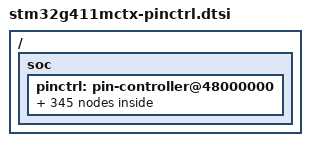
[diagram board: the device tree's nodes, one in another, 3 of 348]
/*
 * NOTE: Autogenerated file using genpinctrl.py
 *
 * SPDX-License-Identifier: Apache-2.0
 */

#include <zephyr/dt-bindings/pinctrl/stm32-pinctrl.h>

/ {
	soc {
		pinctrl: pin-controller@48000000 {

			/* ADC_IN / ADC_INN / ADC_INP */

			/omit-if-no-ref/ adc1_in1_pa0: adc1_in1_pa0 {
				pinmux = <STM32_PINMUX('A', 0, ANALOG)>;
			};

			/omit-if-no-ref/ adc1_in2_pa1: adc1_in2_pa1 {
				pinmux = <STM32_PINMUX('A', 1, ANALOG)>;
			};

			/omit-if-no-ref/ adc1_in3_pa2: adc1_in3_pa2 {
				pinmux = <STM32_PINMUX('A', 2, ANALOG)>;
			};

			/omit-if-no-ref/ adc1_in4_pa3: adc1_in4_pa3 {
				pinmux = <STM32_PINMUX('A', 3, ANALOG)>;
			};

			/omit-if-no-ref/ adc1_in15_pb0: adc1_in15_pb0 {
				pinmux = <STM32_PINMUX('B', 0, ANALOG)>;
			};

			/omit-if-no-ref/ adc1_in12_pb1: adc1_in12_pb1 {
				pinmux = <STM32_PINMUX('B', 1, ANALOG)>;
			};

			/omit-if-no-ref/ adc1_in14_pb11: adc1_in14_pb11 {
				pinmux = <STM32_PINMUX('B', 11, ANALOG)>;
			};

			/omit-if-no-ref/ adc1_in11_pb12: adc1_in11_pb12 {
				pinmux = <STM32_PINMUX('B', 12, ANALOG)>;
			};

			/omit-if-no-ref/ adc1_in5_pb14: adc1_in5_pb14 {
				pinmux = <STM32_PINMUX('B', 14, ANALOG)>;
			};

			/omit-if-no-ref/ adc1_in6_pc0: adc1_in6_pc0 {
				pinmux = <STM32_PINMUX('C', 0, ANALOG)>;
			};

			/omit-if-no-ref/ adc1_in7_pc1: adc1_in7_pc1 {
				pinmux = <STM32_PINMUX('C', 1, ANALOG)>;
			};

			/omit-if-no-ref/ adc1_in8_pc2: adc1_in8_pc2 {
				pinmux = <STM32_PINMUX('C', 2, ANALOG)>;
			};

			/omit-if-no-ref/ adc1_in9_pc3: adc1_in9_pc3 {
				pinmux = <STM32_PINMUX('C', 3, ANALOG)>;
			};

			/omit-if-no-ref/ adc1_in10_pf0: adc1_in10_pf0 {
				pinmux = <STM32_PINMUX('F', 0, ANALOG)>;
			};

			/omit-if-no-ref/ adc2_in1_pa0: adc2_in1_pa0 {
				pinmux = <STM32_PINMUX('A', 0, ANALOG)>;
			};

			/omit-if-no-ref/ adc2_in2_pa1: adc2_in2_pa1 {
				pinmux = <STM32_PINMUX('A', 1, ANALOG)>;
			};

			/omit-if-no-ref/ adc2_in17_pa4: adc2_in17_pa4 {
				pinmux = <STM32_PINMUX('A', 4, ANALOG)>;
			};

			/omit-if-no-ref/ adc2_in13_pa5: adc2_in13_pa5 {
				pinmux = <STM32_PINMUX('A', 5, ANALOG)>;
			};

			/omit-if-no-ref/ adc2_in3_pa6: adc2_in3_pa6 {
				pinmux = <STM32_PINMUX('A', 6, ANALOG)>;
			};

			/omit-if-no-ref/ adc2_in4_pa7: adc2_in4_pa7 {
				pinmux = <STM32_PINMUX('A', 7, ANALOG)>;
			};

			/omit-if-no-ref/ adc2_in12_pb2: adc2_in12_pb2 {
				pinmux = <STM32_PINMUX('B', 2, ANALOG)>;
			};

			/omit-if-no-ref/ adc2_in14_pb11: adc2_in14_pb11 {
				pinmux = <STM32_PINMUX('B', 11, ANALOG)>;
			};

			/omit-if-no-ref/ adc2_in15_pb15: adc2_in15_pb15 {
				pinmux = <STM32_PINMUX('B', 15, ANALOG)>;
			};

			/omit-if-no-ref/ adc2_in6_pc0: adc2_in6_pc0 {
				pinmux = <STM32_PINMUX('C', 0, ANALOG)>;
			};

			/omit-if-no-ref/ adc2_in7_pc1: adc2_in7_pc1 {
				pinmux = <STM32_PINMUX('C', 1, ANALOG)>;
			};

			/omit-if-no-ref/ adc2_in8_pc2: adc2_in8_pc2 {
				pinmux = <STM32_PINMUX('C', 2, ANALOG)>;
			};

			/omit-if-no-ref/ adc2_in9_pc3: adc2_in9_pc3 {
				pinmux = <STM32_PINMUX('C', 3, ANALOG)>;
			};

			/omit-if-no-ref/ adc2_in5_pc4: adc2_in5_pc4 {
				pinmux = <STM32_PINMUX('C', 4, ANALOG)>;
			};

			/omit-if-no-ref/ adc2_in11_pc5: adc2_in11_pc5 {
				pinmux = <STM32_PINMUX('C', 5, ANALOG)>;
			};

			/omit-if-no-ref/ adc2_in10_pf1: adc2_in10_pf1 {
				pinmux = <STM32_PINMUX('F', 1, ANALOG)>;
			};

			/omit-if-no-ref/ adc3_in12_pb0: adc3_in12_pb0 {
				pinmux = <STM32_PINMUX('B', 0, ANALOG)>;
			};

			/omit-if-no-ref/ adc3_in1_pb1: adc3_in1_pb1 {
				pinmux = <STM32_PINMUX('B', 1, ANALOG)>;
			};

			/omit-if-no-ref/ adc3_in5_pb13: adc3_in5_pb13 {
				pinmux = <STM32_PINMUX('B', 13, ANALOG)>;
			};

			/omit-if-no-ref/ adc3_in7_pd10: adc3_in7_pd10 {
				pinmux = <STM32_PINMUX('D', 10, ANALOG)>;
			};

			/omit-if-no-ref/ adc3_in4_pe7: adc3_in4_pe7 {
				pinmux = <STM32_PINMUX('E', 7, ANALOG)>;
			};

			/omit-if-no-ref/ adc3_in6_pe8: adc3_in6_pe8 {
				pinmux = <STM32_PINMUX('E', 8, ANALOG)>;
			};

			/omit-if-no-ref/ adc3_in2_pe9: adc3_in2_pe9 {
				pinmux = <STM32_PINMUX('E', 9, ANALOG)>;
			};

			/omit-if-no-ref/ adc3_in14_pe10: adc3_in14_pe10 {
				pinmux = <STM32_PINMUX('E', 10, ANALOG)>;
			};

			/omit-if-no-ref/ adc3_in15_pe11: adc3_in15_pe11 {
				pinmux = <STM32_PINMUX('E', 11, ANALOG)>;
			};

			/omit-if-no-ref/ adc3_in16_pe12: adc3_in16_pe12 {
				pinmux = <STM32_PINMUX('E', 12, ANALOG)>;
			};

			/omit-if-no-ref/ adc3_in3_pe13: adc3_in3_pe13 {
				pinmux = <STM32_PINMUX('E', 13, ANALOG)>;
			};

			/* Analog */

			/omit-if-no-ref/ analog_pa0: analog_pa0 {
				pinmux = <STM32_PINMUX('A', 0, ANALOG)>;
			};

			/omit-if-no-ref/ analog_pa1: analog_pa1 {
				pinmux = <STM32_PINMUX('A', 1, ANALOG)>;
			};

			/omit-if-no-ref/ analog_pa2: analog_pa2 {
				pinmux = <STM32_PINMUX('A', 2, ANALOG)>;
			};

			/omit-if-no-ref/ analog_pa3: analog_pa3 {
				pinmux = <STM32_PINMUX('A', 3, ANALOG)>;
			};

			/omit-if-no-ref/ analog_pa4: analog_pa4 {
				pinmux = <STM32_PINMUX('A', 4, ANALOG)>;
			};

			/omit-if-no-ref/ analog_pa5: analog_pa5 {
				pinmux = <STM32_PINMUX('A', 5, ANALOG)>;
			};

			/omit-if-no-ref/ analog_pa6: analog_pa6 {
				pinmux = <STM32_PINMUX('A', 6, ANALOG)>;
			};

			/omit-if-no-ref/ analog_pa7: analog_pa7 {
				pinmux = <STM32_PINMUX('A', 7, ANALOG)>;
			};

			/omit-if-no-ref/ analog_pa8: analog_pa8 {
				pinmux = <STM32_PINMUX('A', 8, ANALOG)>;
			};

			/omit-if-no-ref/ analog_pa9: analog_pa9 {
				pinmux = <STM32_PINMUX('A', 9, ANALOG)>;
			};

			/omit-if-no-ref/ analog_pa10: analog_pa10 {
				pinmux = <STM32_PINMUX('A', 10, ANALOG)>;
			};

			/omit-if-no-ref/ analog_pa11: analog_pa11 {
				pinmux = <STM32_PINMUX('A', 11, ANALOG)>;
			};

			/omit-if-no-ref/ analog_pa12: analog_pa12 {
				pinmux = <STM32_PINMUX('A', 12, ANALOG)>;
			};

			/omit-if-no-ref/ analog_pa13: analog_pa13 {
				pinmux = <STM32_PINMUX('A', 13, ANALOG)>;
			};

			/omit-if-no-ref/ analog_pa14: analog_pa14 {
				pinmux = <STM32_PINMUX('A', 14, ANALOG)>;
			};

			/omit-if-no-ref/ analog_pa15: analog_pa15 {
				pinmux = <STM32_PINMUX('A', 15, ANALOG)>;
			};

			/omit-if-no-ref/ analog_pb0: analog_pb0 {
				pinmux = <STM32_PINMUX('B', 0, ANALOG)>;
			};

			/omit-if-no-ref/ analog_pb1: analog_pb1 {
				pinmux = <STM32_PINMUX('B', 1, ANALOG)>;
			};

			/omit-if-no-ref/ analog_pb2: analog_pb2 {
				pinmux = <STM32_PINMUX('B', 2, ANALOG)>;
			};

			/omit-if-no-ref/ analog_pb3: analog_pb3 {
				pinmux = <STM32_PINMUX('B', 3, ANALOG)>;
			};

			/omit-if-no-ref/ analog_pb4: analog_pb4 {
				pinmux = <STM32_PINMUX('B', 4, ANALOG)>;
			};

			/omit-if-no-ref/ analog_pb5: analog_pb5 {
				pinmux = <STM32_PINMUX('B', 5, ANALOG)>;
			};

			/omit-if-no-ref/ analog_pb6: analog_pb6 {
				pinmux = <STM32_PINMUX('B', 6, ANALOG)>;
			};

			/omit-if-no-ref/ analog_pb7: analog_pb7 {
				pinmux = <STM32_PINMUX('B', 7, ANALOG)>;
			};

			/omit-if-no-ref/ analog_pb8: analog_pb8 {
				pinmux = <STM32_PINMUX('B', 8, ANALOG)>;
			};

			/omit-if-no-ref/ analog_pb9: analog_pb9 {
				pinmux = <STM32_PINMUX('B', 9, ANALOG)>;
			};

			/omit-if-no-ref/ analog_pb10: analog_pb10 {
				pinmux = <STM32_PINMUX('B', 10, ANALOG)>;
			};

			/omit-if-no-ref/ analog_pb11: analog_pb11 {
				pinmux = <STM32_PINMUX('B', 11, ANALOG)>;
			};

			/omit-if-no-ref/ analog_pb12: analog_pb12 {
				pinmux = <STM32_PINMUX('B', 12, ANALOG)>;
			};

			/omit-if-no-ref/ analog_pb13: analog_pb13 {
				pinmux = <STM32_PINMUX('B', 13, ANALOG)>;
			};

			/omit-if-no-ref/ analog_pb14: analog_pb14 {
				pinmux = <STM32_PINMUX('B', 14, ANALOG)>;
			};

			/omit-if-no-ref/ analog_pb15: analog_pb15 {
				pinmux = <STM32_PINMUX('B', 15, ANALOG)>;
			};

			/omit-if-no-ref/ analog_pc0: analog_pc0 {
				pinmux = <STM32_PINMUX('C', 0, ANALOG)>;
			};

			/omit-if-no-ref/ analog_pc1: analog_pc1 {
				pinmux = <STM32_PINMUX('C', 1, ANALOG)>;
			};

			/omit-if-no-ref/ analog_pc2: analog_pc2 {
				pinmux = <STM32_PINMUX('C', 2, ANALOG)>;
			};

			/omit-if-no-ref/ analog_pc3: analog_pc3 {
				pinmux = <STM32_PINMUX('C', 3, ANALOG)>;
			};

			/omit-if-no-ref/ analog_pc4: analog_pc4 {
				pinmux = <STM32_PINMUX('C', 4, ANALOG)>;
			};

			/omit-if-no-ref/ analog_pc5: analog_pc5 {
				pinmux = <STM32_PINMUX('C', 5, ANALOG)>;
			};

			/omit-if-no-ref/ analog_pc6: analog_pc6 {
				pinmux = <STM32_PINMUX('C', 6, ANALOG)>;
			};

			/omit-if-no-ref/ analog_pc7: analog_pc7 {
				pinmux = <STM32_PINMUX('C', 7, ANALOG)>;
			};

			/omit-if-no-ref/ analog_pc8: analog_pc8 {
				pinmux = <STM32_PINMUX('C', 8, ANALOG)>;
			};

			/omit-if-no-ref/ analog_pc9: analog_pc9 {
				pinmux = <STM32_PINMUX('C', 9, ANALOG)>;
			};

			/omit-if-no-ref/ analog_pc10: analog_pc10 {
				pinmux = <STM32_PINMUX('C', 10, ANALOG)>;
			};

			/omit-if-no-ref/ analog_pc11: analog_pc11 {
				pinmux = <STM32_PINMUX('C', 11, ANALOG)>;
			};

			/omit-if-no-ref/ analog_pc12: analog_pc12 {
				pinmux = <STM32_PINMUX('C', 12, ANALOG)>;
			};

			/omit-if-no-ref/ analog_pc13: analog_pc13 {
				pinmux = <STM32_PINMUX('C', 13, ANALOG)>;
			};

			/omit-if-no-ref/ analog_pc14: analog_pc14 {
				pinmux = <STM32_PINMUX('C', 14, ANALOG)>;
			};

			/omit-if-no-ref/ analog_pc15: analog_pc15 {
				pinmux = <STM32_PINMUX('C', 15, ANALOG)>;
			};

			/omit-if-no-ref/ analog_pd0: analog_pd0 {
				pinmux = <STM32_PINMUX('D', 0, ANALOG)>;
			};

			/omit-if-no-ref/ analog_pd1: analog_pd1 {
				pinmux = <STM32_PINMUX('D', 1, ANALOG)>;
			};

			/omit-if-no-ref/ analog_pd2: analog_pd2 {
				pinmux = <STM32_PINMUX('D', 2, ANALOG)>;
			};

			/omit-if-no-ref/ analog_pd8: analog_pd8 {
				pinmux = <STM32_PINMUX('D', 8, ANALOG)>;
			};

			/omit-if-no-ref/ analog_pd9: analog_pd9 {
				pinmux = <STM32_PINMUX('D', 9, ANALOG)>;
			};

			/omit-if-no-ref/ analog_pd10: analog_pd10 {
				pinmux = <STM32_PINMUX('D', 10, ANALOG)>;
			};

			/omit-if-no-ref/ analog_pe7: analog_pe7 {
				pinmux = <STM32_PINMUX('E', 7, ANALOG)>;
			};

			/omit-if-no-ref/ analog_pe8: analog_pe8 {
				pinmux = <STM32_PINMUX('E', 8, ANALOG)>;
			};

			/omit-if-no-ref/ analog_pe9: analog_pe9 {
				pinmux = <STM32_PINMUX('E', 9, ANALOG)>;
			};

			/omit-if-no-ref/ analog_pe10: analog_pe10 {
				pinmux = <STM32_PINMUX('E', 10, ANALOG)>;
			};

			/omit-if-no-ref/ analog_pe11: analog_pe11 {
				pinmux = <STM32_PINMUX('E', 11, ANALOG)>;
			};

			/omit-if-no-ref/ analog_pe12: analog_pe12 {
				pinmux = <STM32_PINMUX('E', 12, ANALOG)>;
			};

			/omit-if-no-ref/ analog_pe13: analog_pe13 {
				pinmux = <STM32_PINMUX('E', 13, ANALOG)>;
			};

			/omit-if-no-ref/ analog_pe14: analog_pe14 {
				pinmux = <STM32_PINMUX('E', 14, ANALOG)>;
			};

			/omit-if-no-ref/ analog_pe15: analog_pe15 {
				pinmux = <STM32_PINMUX('E', 15, ANALOG)>;
			};

			/omit-if-no-ref/ analog_pf0: analog_pf0 {
				pinmux = <STM32_PINMUX('F', 0, ANALOG)>;
			};

			/omit-if-no-ref/ analog_pf1: analog_pf1 {
				pinmux = <STM32_PINMUX('F', 1, ANALOG)>;
			};

			/omit-if-no-ref/ analog_pg10: analog_pg10 {
				pinmux = <STM32_PINMUX('G', 10, ANALOG)>;
			};

			/* COMP_IN */

			/omit-if-no-ref/ comp1_inm_pa0: comp1_inm_pa0 {
				pinmux = <STM32_PINMUX('A', 0, ANALOG)>;
			};

			/omit-if-no-ref/ comp1_inp_pa1: comp1_inp_pa1 {
				pinmux = <STM32_PINMUX('A', 1, ANALOG)>;
			};

			/omit-if-no-ref/ comp1_inm_pa4: comp1_inm_pa4 {
				pinmux = <STM32_PINMUX('A', 4, ANALOG)>;
			};

			/omit-if-no-ref/ comp1_inp_pb1: comp1_inp_pb1 {
				pinmux = <STM32_PINMUX('B', 1, ANALOG)>;
			};

			/omit-if-no-ref/ comp2_inm_pa2: comp2_inm_pa2 {
				pinmux = <STM32_PINMUX('A', 2, ANALOG)>;
			};

			/omit-if-no-ref/ comp2_inp_pa3: comp2_inp_pa3 {
				pinmux = <STM32_PINMUX('A', 3, ANALOG)>;
			};

			/omit-if-no-ref/ comp2_inm_pa5: comp2_inm_pa5 {
				pinmux = <STM32_PINMUX('A', 5, ANALOG)>;
			};

			/omit-if-no-ref/ comp2_inp_pa7: comp2_inp_pa7 {
				pinmux = <STM32_PINMUX('A', 7, ANALOG)>;
			};

			/omit-if-no-ref/ comp3_inp_pa0: comp3_inp_pa0 {
				pinmux = <STM32_PINMUX('A', 0, ANALOG)>;
			};

			/omit-if-no-ref/ comp3_inm_pc0: comp3_inm_pc0 {
				pinmux = <STM32_PINMUX('C', 0, ANALOG)>;
			};

			/omit-if-no-ref/ comp3_inp_pc1: comp3_inp_pc1 {
				pinmux = <STM32_PINMUX('C', 1, ANALOG)>;
			};

			/omit-if-no-ref/ comp3_inm_pf1: comp3_inm_pf1 {
				pinmux = <STM32_PINMUX('F', 1, ANALOG)>;
			};

			/* COMP_OUT */

			/omit-if-no-ref/ comp1_out_pa0: comp1_out_pa0 {
				pinmux = <STM32_PINMUX('A', 0, AF8)>;
			};

			/omit-if-no-ref/ comp1_out_pa6: comp1_out_pa6 {
				pinmux = <STM32_PINMUX('A', 6, AF8)>;
			};

			/omit-if-no-ref/ comp1_out_pa11: comp1_out_pa11 {
				pinmux = <STM32_PINMUX('A', 11, AF8)>;
			};

			/omit-if-no-ref/ comp1_out_pb8: comp1_out_pb8 {
				pinmux = <STM32_PINMUX('B', 8, AF8)>;
			};

			/omit-if-no-ref/ comp2_out_pa2: comp2_out_pa2 {
				pinmux = <STM32_PINMUX('A', 2, AF8)>;
			};

			/omit-if-no-ref/ comp2_out_pa7: comp2_out_pa7 {
				pinmux = <STM32_PINMUX('A', 7, AF8)>;
			};

			/omit-if-no-ref/ comp2_out_pa12: comp2_out_pa12 {
				pinmux = <STM32_PINMUX('A', 12, AF8)>;
			};

			/omit-if-no-ref/ comp2_out_pb9: comp2_out_pb9 {
				pinmux = <STM32_PINMUX('B', 9, AF8)>;
			};

			/omit-if-no-ref/ comp3_out_pb7: comp3_out_pb7 {
				pinmux = <STM32_PINMUX('B', 7, AF8)>;
			};

			/omit-if-no-ref/ comp3_out_pb15: comp3_out_pb15 {
				pinmux = <STM32_PINMUX('B', 15, AF3)>;
			};

			/omit-if-no-ref/ comp3_out_pc2: comp3_out_pc2 {
				pinmux = <STM32_PINMUX('C', 2, AF3)>;
			};

			/* DAC_OUT */

			/omit-if-no-ref/ dac1_out1_pa4: dac1_out1_pa4 {
				pinmux = <STM32_PINMUX('A', 4, ANALOG)>;
			};

			/omit-if-no-ref/ dac1_out2_pa5: dac1_out2_pa5 {
				pinmux = <STM32_PINMUX('A', 5, ANALOG)>;
			};

			/* FDCAN_RX */

			/omit-if-no-ref/ fdcan1_rx_pa11: fdcan1_rx_pa11 {
				pinmux = <STM32_PINMUX('A', 11, AF9)>;
			};

			/omit-if-no-ref/ fdcan1_rx_pb8: fdcan1_rx_pb8 {
				pinmux = <STM32_PINMUX('B', 8, AF9)>;
			};

			/omit-if-no-ref/ fdcan1_rx_pd0: fdcan1_rx_pd0 {
				pinmux = <STM32_PINMUX('D', 0, AF9)>;
			};

			/* FDCAN_TX */

			/omit-if-no-ref/ fdcan1_tx_pa12: fdcan1_tx_pa12 {
				pinmux = <STM32_PINMUX('A', 12, AF9)>;
			};

			/omit-if-no-ref/ fdcan1_tx_pb9: fdcan1_tx_pb9 {
				pinmux = <STM32_PINMUX('B', 9, AF9)>;
			};

			/omit-if-no-ref/ fdcan1_tx_pd1: fdcan1_tx_pd1 {
				pinmux = <STM32_PINMUX('D', 1, AF9)>;
			};

			/* I2C_SCL */

			/omit-if-no-ref/ i2c1_scl_pa13: i2c1_scl_pa13 {
				pinmux = <STM32_PINMUX('A', 13, AF4)>;
				bias-pull-up;
				drive-open-drain;
			};

			/omit-if-no-ref/ i2c1_scl_pa15: i2c1_scl_pa15 {
				pinmux = <STM32_PINMUX('A', 15, AF4)>;
				bias-pull-up;
				drive-open-drain;
			};

			/omit-if-no-ref/ i2c1_scl_pb8: i2c1_scl_pb8 {
				pinmux = <STM32_PINMUX('B', 8, AF4)>;
				bias-pull-up;
				drive-open-drain;
			};

			/omit-if-no-ref/ i2c2_scl_pa9: i2c2_scl_pa9 {
				pinmux = <STM32_PINMUX('A', 9, AF4)>;
				bias-pull-up;
				drive-open-drain;
			};

			/omit-if-no-ref/ i2c2_scl_pc4: i2c2_scl_pc4 {
				pinmux = <STM32_PINMUX('C', 4, AF4)>;
				bias-pull-up;
				drive-open-drain;
			};

			/* I2C_SDA */

			/omit-if-no-ref/ i2c1_sda_pa14: i2c1_sda_pa14 {
				pinmux = <STM32_PINMUX('A', 14, AF4)>;
				bias-pull-up;
				drive-open-drain;
			};

			/omit-if-no-ref/ i2c1_sda_pb7: i2c1_sda_pb7 {
				pinmux = <STM32_PINMUX('B', 7, AF4)>;
				bias-pull-up;
				drive-open-drain;
			};

			/omit-if-no-ref/ i2c1_sda_pb9: i2c1_sda_pb9 {
				pinmux = <STM32_PINMUX('B', 9, AF4)>;
				bias-pull-up;
				drive-open-drain;
			};

			/omit-if-no-ref/ i2c2_sda_pa8: i2c2_sda_pa8 {
				pinmux = <STM32_PINMUX('A', 8, AF4)>;
				bias-pull-up;
				drive-open-drain;
			};

			/omit-if-no-ref/ i2c2_sda_pf0: i2c2_sda_pf0 {
				pinmux = <STM32_PINMUX('F', 0, AF4)>;
				bias-pull-up;
				drive-open-drain;
			};

			/* I2C_SMBA */

			/omit-if-no-ref/ i2c1_smba_pb5: i2c1_smba_pb5 {
				pinmux = <STM32_PINMUX('B', 5, AF4)>;
				bias-pull-up;
			};

			/omit-if-no-ref/ i2c2_smba_pa10: i2c2_smba_pa10 {
				pinmux = <STM32_PINMUX('A', 10, AF4)>;
				bias-pull-up;
			};

			/omit-if-no-ref/ i2c2_smba_pb12: i2c2_smba_pb12 {
				pinmux = <STM32_PINMUX('B', 12, AF4)>;
				bias-pull-up;
			};

			/* I2S_CK */

			/omit-if-no-ref/ i2s2_ck_pb13: i2s2_ck_pb13 {
				pinmux = <STM32_PINMUX('B', 13, AF5)>;
				slew-rate = "very-high-speed";
			};

			/omit-if-no-ref/ i2s2_ck_pf1: i2s2_ck_pf1 {
				pinmux = <STM32_PINMUX('F', 1, AF5)>;
				slew-rate = "very-high-speed";
			};

			/* I2S_MCK */

			/omit-if-no-ref/ i2s2_mck_pa8: i2s2_mck_pa8 {
				pinmux = <STM32_PINMUX('A', 8, AF5)>;
				slew-rate = "very-high-speed";
			};

			/omit-if-no-ref/ i2s2_mck_pc6: i2s2_mck_pc6 {
				pinmux = <STM32_PINMUX('C', 6, AF6)>;
				slew-rate = "very-high-speed";
			};

			/* I2S_SD */

			/omit-if-no-ref/ i2s2_sd_pa11: i2s2_sd_pa11 {
				pinmux = <STM32_PINMUX('A', 11, AF5)>;
			};

			/omit-if-no-ref/ i2s2_sd_pb15: i2s2_sd_pb15 {
				pinmux = <STM32_PINMUX('B', 15, AF5)>;
			};

			/* I2S_WS */

			/omit-if-no-ref/ i2s2_ws_pb12: i2s2_ws_pb12 {
				pinmux = <STM32_PINMUX('B', 12, AF5)>;
			};

			/omit-if-no-ref/ i2s2_ws_pf0: i2s2_ws_pf0 {
				pinmux = <STM32_PINMUX('F', 0, AF5)>;
			};

			/* JTAG PORT */

			/omit-if-no-ref/ sys_jtms_swdio_pa13: sys_jtms_swdio_pa13 {
				pinmux = <STM32_PINMUX('A', 13, AF0)>;
			};

			/omit-if-no-ref/ sys_jtck_swclk_pa14: sys_jtck_swclk_pa14 {
				pinmux = <STM32_PINMUX('A', 14, AF0)>;
			};

			/omit-if-no-ref/ sys_jtdi_pa15: sys_jtdi_pa15 {
				pinmux = <STM32_PINMUX('A', 15, AF0)>;
			};

			/omit-if-no-ref/ sys_jtdo_swo_pb3: sys_jtdo_swo_pb3 {
				pinmux = <STM32_PINMUX('B', 3, AF0)>;
			};

			/omit-if-no-ref/ sys_jtrst_pb4: sys_jtrst_pb4 {
				pinmux = <STM32_PINMUX('B', 4, AF0)>;
			};

			/* OPAMP */

			/omit-if-no-ref/ opamp1_vinp_pa1: opamp1_vinp_pa1 {
				pinmux = <STM32_PINMUX('A', 1, ANALOG)>;
			};

			/omit-if-no-ref/ opamp1_vout_pa2: opamp1_vout_pa2 {
				pinmux = <STM32_PINMUX('A', 2, ANALOG)>;
			};

			/omit-if-no-ref/ opamp1_vinm_pa3: opamp1_vinm_pa3 {
				pinmux = <STM32_PINMUX('A', 3, ANALOG)>;
			};

			/omit-if-no-ref/ opamp1_vinp_pa3: opamp1_vinp_pa3 {
				pinmux = <STM32_PINMUX('A', 3, ANALOG)>;
			};

			/omit-if-no-ref/ opamp1_vinp_pa7: opamp1_vinp_pa7 {
				pinmux = <STM32_PINMUX('A', 7, ANALOG)>;
			};

			/omit-if-no-ref/ opamp1_vinm_pc5: opamp1_vinm_pc5 {
				pinmux = <STM32_PINMUX('C', 5, ANALOG)>;
			};

			/* RCC_MCO */

			/omit-if-no-ref/ rcc_mco_pa8: rcc_mco_pa8 {
				pinmux = <STM32_PINMUX('A', 8, AF0)>;
				slew-rate = "very-high-speed";
			};

			/omit-if-no-ref/ rcc_mco_pg10: rcc_mco_pg10 {
				pinmux = <STM32_PINMUX('G', 10, AF0)>;
				slew-rate = "very-high-speed";
			};

			/* SPI_MISO */

			/omit-if-no-ref/ spi1_miso_pa6: spi1_miso_pa6 {
				pinmux = <STM32_PINMUX('A', 6, AF5)>;
				bias-pull-down;
			};

			/omit-if-no-ref/ spi1_miso_pb4: spi1_miso_pb4 {
				pinmux = <STM32_PINMUX('B', 4, AF5)>;
				bias-pull-down;
			};

			/omit-if-no-ref/ spi2_miso_pa10: spi2_miso_pa10 {
				pinmux = <STM32_PINMUX('A', 10, AF5)>;
				bias-pull-down;
			};

			/omit-if-no-ref/ spi2_miso_pb14: spi2_miso_pb14 {
				pinmux = <STM32_PINMUX('B', 14, AF5)>;
				bias-pull-down;
			};

			/* SPI_MOSI */

			/omit-if-no-ref/ spi1_mosi_pa7: spi1_mosi_pa7 {
				pinmux = <STM32_PINMUX('A', 7, AF5)>;
				bias-pull-down;
			};

			/omit-if-no-ref/ spi1_mosi_pb5: spi1_mosi_pb5 {
				pinmux = <STM32_PINMUX('B', 5, AF5)>;
				bias-pull-down;
			};

			/omit-if-no-ref/ spi2_mosi_pa11: spi2_mosi_pa11 {
				pinmux = <STM32_PINMUX('A', 11, AF5)>;
				bias-pull-down;
			};

			/omit-if-no-ref/ spi2_mosi_pb15: spi2_mosi_pb15 {
				pinmux = <STM32_PINMUX('B', 15, AF5)>;
				bias-pull-down;
			};

			/* SPI_NSS */

			/omit-if-no-ref/ spi1_nss_pa4: spi1_nss_pa4 {
				pinmux = <STM32_PINMUX('A', 4, AF5)>;
				bias-pull-up;
			};

			/omit-if-no-ref/ spi1_nss_pa15: spi1_nss_pa15 {
				pinmux = <STM32_PINMUX('A', 15, AF5)>;
				bias-pull-up;
			};

			/omit-if-no-ref/ spi2_nss_pb12: spi2_nss_pb12 {
				pinmux = <STM32_PINMUX('B', 12, AF5)>;
				bias-pull-up;
			};

			/omit-if-no-ref/ spi2_nss_pf0: spi2_nss_pf0 {
				pinmux = <STM32_PINMUX('F', 0, AF5)>;
				bias-pull-up;
			};

			/* SPI_SCK */

			/omit-if-no-ref/ spi1_sck_pa5: spi1_sck_pa5 {
				pinmux = <STM32_PINMUX('A', 5, AF5)>;
				bias-pull-down;
				slew-rate = "very-high-speed";
			};

			/omit-if-no-ref/ spi1_sck_pb3: spi1_sck_pb3 {
				pinmux = <STM32_PINMUX('B', 3, AF5)>;
				bias-pull-down;
				slew-rate = "very-high-speed";
			};

			/omit-if-no-ref/ spi2_sck_pb13: spi2_sck_pb13 {
				pinmux = <STM32_PINMUX('B', 13, AF5)>;
				bias-pull-down;
				slew-rate = "very-high-speed";
			};

			/omit-if-no-ref/ spi2_sck_pf1: spi2_sck_pf1 {
				pinmux = <STM32_PINMUX('F', 1, AF5)>;
				bias-pull-down;
				slew-rate = "very-high-speed";
			};

			/* TIM_BKIN */

			/omit-if-no-ref/ tim1_bkin_pa6: tim1_bkin_pa6 {
				pinmux = <STM32_PINMUX('A', 6, AF6)>;
			};

			/omit-if-no-ref/ tim1_bkin2_pa11: tim1_bkin2_pa11 {
				pinmux = <STM32_PINMUX('A', 11, AF12)>;
			};

			/omit-if-no-ref/ tim1_bkin_pa14: tim1_bkin_pa14 {
				pinmux = <STM32_PINMUX('A', 14, AF6)>;
			};

			/omit-if-no-ref/ tim1_bkin_pa15: tim1_bkin_pa15 {
				pinmux = <STM32_PINMUX('A', 15, AF9)>;
			};

			/omit-if-no-ref/ tim1_bkin_pb8: tim1_bkin_pb8 {
				pinmux = <STM32_PINMUX('B', 8, AF12)>;
			};

			/omit-if-no-ref/ tim1_bkin_pb10: tim1_bkin_pb10 {
				pinmux = <STM32_PINMUX('B', 10, AF12)>;
			};

			/omit-if-no-ref/ tim1_bkin_pb12: tim1_bkin_pb12 {
				pinmux = <STM32_PINMUX('B', 12, AF6)>;
			};

			/omit-if-no-ref/ tim1_bkin2_pc3: tim1_bkin2_pc3 {
				pinmux = <STM32_PINMUX('C', 3, AF6)>;
			};

			/omit-if-no-ref/ tim1_bkin_pc13: tim1_bkin_pc13 {
				pinmux = <STM32_PINMUX('C', 13, AF2)>;
			};

			/omit-if-no-ref/ tim1_bkin2_pe14: tim1_bkin2_pe14 {
				pinmux = <STM32_PINMUX('E', 14, AF6)>;
			};

			/omit-if-no-ref/ tim1_bkin_pe15: tim1_bkin_pe15 {
				pinmux = <STM32_PINMUX('E', 15, AF2)>;
			};

			/omit-if-no-ref/ tim15_bkin_pa9: tim15_bkin_pa9 {
				pinmux = <STM32_PINMUX('A', 9, AF9)>;
			};

			/omit-if-no-ref/ tim15_bkin_pc5: tim15_bkin_pc5 {
				pinmux = <STM32_PINMUX('C', 5, AF2)>;
			};

			/omit-if-no-ref/ tim16_bkin_pb5: tim16_bkin_pb5 {
				pinmux = <STM32_PINMUX('B', 5, AF1)>;
			};

			/omit-if-no-ref/ tim17_bkin_pa10: tim17_bkin_pa10 {
				pinmux = <STM32_PINMUX('A', 10, AF1)>;
			};

			/omit-if-no-ref/ tim17_bkin_pb4: tim17_bkin_pb4 {
				pinmux = <STM32_PINMUX('B', 4, AF10)>;
			};

			/omit-if-no-ref/ tim8_bkin_pa0: tim8_bkin_pa0 {
				pinmux = <STM32_PINMUX('A', 0, AF9)>;
			};

			/omit-if-no-ref/ tim8_bkin_pa6: tim8_bkin_pa6 {
				pinmux = <STM32_PINMUX('A', 6, AF4)>;
			};

			/omit-if-no-ref/ tim8_bkin_pa10: tim8_bkin_pa10 {
				pinmux = <STM32_PINMUX('A', 10, AF11)>;
			};

			/omit-if-no-ref/ tim8_bkin2_pb6: tim8_bkin2_pb6 {
				pinmux = <STM32_PINMUX('B', 6, AF10)>;
			};

			/omit-if-no-ref/ tim8_bkin_pb7: tim8_bkin_pb7 {
				pinmux = <STM32_PINMUX('B', 7, AF5)>;
			};

			/omit-if-no-ref/ tim8_bkin2_pc9: tim8_bkin2_pc9 {
				pinmux = <STM32_PINMUX('C', 9, AF6)>;
			};

			/omit-if-no-ref/ tim8_bkin2_pd1: tim8_bkin2_pd1 {
				pinmux = <STM32_PINMUX('D', 1, AF6)>;
			};

			/omit-if-no-ref/ tim8_bkin_pd2: tim8_bkin_pd2 {
				pinmux = <STM32_PINMUX('D', 2, AF4)>;
			};

			/* TIM_CH / TIM_CHN */

			/omit-if-no-ref/ tim20_ch1_pb2: tim20_ch1_pb2 {
				pinmux = <STM32_PINMUX('B', 2, AF3)>;
			};

			/omit-if-no-ref/ tim20_ch2_pc2: tim20_ch2_pc2 {
				pinmux = <STM32_PINMUX('C', 2, AF6)>;
			};

			/omit-if-no-ref/ tim20_ch3_pc8: tim20_ch3_pc8 {
				pinmux = <STM32_PINMUX('C', 8, AF6)>;
			};

			/omit-if-no-ref/ tim1_ch1n_pa7: tim1_ch1n_pa7 {
				pinmux = <STM32_PINMUX('A', 7, AF6)>;
			};

			/omit-if-no-ref/ tim1_ch1_pa8: tim1_ch1_pa8 {
				pinmux = <STM32_PINMUX('A', 8, AF6)>;
			};

			/omit-if-no-ref/ tim1_ch2_pa9: tim1_ch2_pa9 {
				pinmux = <STM32_PINMUX('A', 9, AF6)>;
			};

			/omit-if-no-ref/ tim1_ch3_pa10: tim1_ch3_pa10 {
				pinmux = <STM32_PINMUX('A', 10, AF6)>;
			};

			/omit-if-no-ref/ tim1_ch1n_pa11: tim1_ch1n_pa11 {
				pinmux = <STM32_PINMUX('A', 11, AF6)>;
			};

			/omit-if-no-ref/ tim1_ch4_pa11: tim1_ch4_pa11 {
				pinmux = <STM32_PINMUX('A', 11, AF11)>;
			};

			/omit-if-no-ref/ tim1_ch2n_pa12: tim1_ch2n_pa12 {
				pinmux = <STM32_PINMUX('A', 12, AF6)>;
			};

			/omit-if-no-ref/ tim1_ch2n_pb0: tim1_ch2n_pb0 {
				pinmux = <STM32_PINMUX('B', 0, AF6)>;
			};

			/omit-if-no-ref/ tim1_ch3n_pb1: tim1_ch3n_pb1 {
				pinmux = <STM32_PINMUX('B', 1, AF6)>;
			};

			/omit-if-no-ref/ tim1_ch3n_pb9: tim1_ch3n_pb9 {
				pinmux = <STM32_PINMUX('B', 9, AF12)>;
			};

			/omit-if-no-ref/ tim1_ch1n_pb13: tim1_ch1n_pb13 {
				pinmux = <STM32_PINMUX('B', 13, AF6)>;
			};

			/omit-if-no-ref/ tim1_ch2n_pb14: tim1_ch2n_pb14 {
				pinmux = <STM32_PINMUX('B', 14, AF6)>;
			};

			/omit-if-no-ref/ tim1_ch3n_pb15: tim1_ch3n_pb15 {
				pinmux = <STM32_PINMUX('B', 15, AF4)>;
			};

			/omit-if-no-ref/ tim1_ch1_pc0: tim1_ch1_pc0 {
				pinmux = <STM32_PINMUX('C', 0, AF2)>;
			};

			/omit-if-no-ref/ tim1_ch2_pc1: tim1_ch2_pc1 {
				pinmux = <STM32_PINMUX('C', 1, AF2)>;
			};

			/omit-if-no-ref/ tim1_ch3_pc2: tim1_ch3_pc2 {
				pinmux = <STM32_PINMUX('C', 2, AF2)>;
			};

			/omit-if-no-ref/ tim1_ch4_pc3: tim1_ch4_pc3 {
				pinmux = <STM32_PINMUX('C', 3, AF2)>;
			};

			/omit-if-no-ref/ tim1_ch4n_pc5: tim1_ch4n_pc5 {
				pinmux = <STM32_PINMUX('C', 5, AF6)>;
			};

			/omit-if-no-ref/ tim1_ch1n_pc13: tim1_ch1n_pc13 {
				pinmux = <STM32_PINMUX('C', 13, AF4)>;
			};

			/omit-if-no-ref/ tim1_ch1n_pe8: tim1_ch1n_pe8 {
				pinmux = <STM32_PINMUX('E', 8, AF2)>;
			};

			/omit-if-no-ref/ tim1_ch1_pe9: tim1_ch1_pe9 {
				pinmux = <STM32_PINMUX('E', 9, AF2)>;
			};

			/omit-if-no-ref/ tim1_ch2n_pe10: tim1_ch2n_pe10 {
				pinmux = <STM32_PINMUX('E', 10, AF2)>;
			};

			/omit-if-no-ref/ tim1_ch2_pe11: tim1_ch2_pe11 {
				pinmux = <STM32_PINMUX('E', 11, AF2)>;
			};

			/omit-if-no-ref/ tim1_ch3n_pe12: tim1_ch3n_pe12 {
				pinmux = <STM32_PINMUX('E', 12, AF2)>;
			};

			/omit-if-no-ref/ tim1_ch3_pe13: tim1_ch3_pe13 {
				pinmux = <STM32_PINMUX('E', 13, AF2)>;
			};

			/omit-if-no-ref/ tim1_ch4_pe14: tim1_ch4_pe14 {
				pinmux = <STM32_PINMUX('E', 14, AF2)>;
			};

			/omit-if-no-ref/ tim1_ch4n_pe15: tim1_ch4n_pe15 {
				pinmux = <STM32_PINMUX('E', 15, AF6)>;
			};

			/omit-if-no-ref/ tim1_ch3n_pf0: tim1_ch3n_pf0 {
				pinmux = <STM32_PINMUX('F', 0, AF6)>;
			};

			/omit-if-no-ref/ tim2_ch1_pa0: tim2_ch1_pa0 {
				pinmux = <STM32_PINMUX('A', 0, AF1)>;
			};

			/omit-if-no-ref/ tim2_ch2_pa1: tim2_ch2_pa1 {
				pinmux = <STM32_PINMUX('A', 1, AF1)>;
			};

			/omit-if-no-ref/ tim2_ch3_pa2: tim2_ch3_pa2 {
				pinmux = <STM32_PINMUX('A', 2, AF1)>;
			};

			/omit-if-no-ref/ tim2_ch4_pa3: tim2_ch4_pa3 {
				pinmux = <STM32_PINMUX('A', 3, AF1)>;
			};

			/omit-if-no-ref/ tim2_ch1_pa5: tim2_ch1_pa5 {
				pinmux = <STM32_PINMUX('A', 5, AF1)>;
			};

			/omit-if-no-ref/ tim2_ch3_pa9: tim2_ch3_pa9 {
				pinmux = <STM32_PINMUX('A', 9, AF10)>;
			};

			/omit-if-no-ref/ tim2_ch4_pa10: tim2_ch4_pa10 {
				pinmux = <STM32_PINMUX('A', 10, AF10)>;
			};

			/omit-if-no-ref/ tim2_ch1_pa15: tim2_ch1_pa15 {
				pinmux = <STM32_PINMUX('A', 15, AF1)>;
			};

			/omit-if-no-ref/ tim2_ch2_pb3: tim2_ch2_pb3 {
				pinmux = <STM32_PINMUX('B', 3, AF1)>;
			};

			/omit-if-no-ref/ tim2_ch3_pb10: tim2_ch3_pb10 {
				pinmux = <STM32_PINMUX('B', 10, AF1)>;
			};

			/omit-if-no-ref/ tim2_ch4_pb11: tim2_ch4_pb11 {
				pinmux = <STM32_PINMUX('B', 11, AF1)>;
			};

			/omit-if-no-ref/ tim3_ch2_pa4: tim3_ch2_pa4 {
				pinmux = <STM32_PINMUX('A', 4, AF2)>;
			};

			/omit-if-no-ref/ tim3_ch1_pa6: tim3_ch1_pa6 {
				pinmux = <STM32_PINMUX('A', 6, AF2)>;
			};

			/omit-if-no-ref/ tim3_ch2_pa7: tim3_ch2_pa7 {
				pinmux = <STM32_PINMUX('A', 7, AF2)>;
			};

			/omit-if-no-ref/ tim3_ch3_pb0: tim3_ch3_pb0 {
				pinmux = <STM32_PINMUX('B', 0, AF2)>;
			};

			/omit-if-no-ref/ tim3_ch4_pb1: tim3_ch4_pb1 {
				pinmux = <STM32_PINMUX('B', 1, AF2)>;
			};

			/omit-if-no-ref/ tim3_ch1_pb4: tim3_ch1_pb4 {
				pinmux = <STM32_PINMUX('B', 4, AF2)>;
			};

			/omit-if-no-ref/ tim3_ch2_pb5: tim3_ch2_pb5 {
				pinmux = <STM32_PINMUX('B', 5, AF2)>;
			};

			/omit-if-no-ref/ tim3_ch4_pb7: tim3_ch4_pb7 {
				pinmux = <STM32_PINMUX('B', 7, AF10)>;
			};

			/omit-if-no-ref/ tim3_ch1_pc6: tim3_ch1_pc6 {
				pinmux = <STM32_PINMUX('C', 6, AF2)>;
			};

			/omit-if-no-ref/ tim3_ch2_pc7: tim3_ch2_pc7 {
				pinmux = <STM32_PINMUX('C', 7, AF2)>;
			};

			/omit-if-no-ref/ tim3_ch3_pc8: tim3_ch3_pc8 {
				pinmux = <STM32_PINMUX('C', 8, AF2)>;
			};

			/omit-if-no-ref/ tim3_ch4_pc9: tim3_ch4_pc9 {
				pinmux = <STM32_PINMUX('C', 9, AF2)>;
			};

			/omit-if-no-ref/ tim4_ch1_pa11: tim4_ch1_pa11 {
				pinmux = <STM32_PINMUX('A', 11, AF10)>;
			};

			/omit-if-no-ref/ tim4_ch2_pa12: tim4_ch2_pa12 {
				pinmux = <STM32_PINMUX('A', 12, AF10)>;
			};

			/omit-if-no-ref/ tim4_ch3_pa13: tim4_ch3_pa13 {
				pinmux = <STM32_PINMUX('A', 13, AF10)>;
			};

			/omit-if-no-ref/ tim4_ch1_pb6: tim4_ch1_pb6 {
				pinmux = <STM32_PINMUX('B', 6, AF2)>;
			};

			/omit-if-no-ref/ tim4_ch2_pb7: tim4_ch2_pb7 {
				pinmux = <STM32_PINMUX('B', 7, AF2)>;
			};

			/omit-if-no-ref/ tim4_ch3_pb8: tim4_ch3_pb8 {
				pinmux = <STM32_PINMUX('B', 8, AF2)>;
			};

			/omit-if-no-ref/ tim4_ch4_pb9: tim4_ch4_pb9 {
				pinmux = <STM32_PINMUX('B', 9, AF2)>;
			};

			/omit-if-no-ref/ tim15_ch1n_pa1: tim15_ch1n_pa1 {
				pinmux = <STM32_PINMUX('A', 1, AF9)>;
			};

			/omit-if-no-ref/ tim15_ch1_pa2: tim15_ch1_pa2 {
				pinmux = <STM32_PINMUX('A', 2, AF9)>;
			};

			/omit-if-no-ref/ tim15_ch2_pa3: tim15_ch2_pa3 {
				pinmux = <STM32_PINMUX('A', 3, AF9)>;
			};

			/omit-if-no-ref/ tim15_ch1_pb14: tim15_ch1_pb14 {
				pinmux = <STM32_PINMUX('B', 14, AF1)>;
			};

			/omit-if-no-ref/ tim15_ch1n_pb15: tim15_ch1n_pb15 {
				pinmux = <STM32_PINMUX('B', 15, AF2)>;
			};

			/omit-if-no-ref/ tim15_ch2_pb15: tim15_ch2_pb15 {
				pinmux = <STM32_PINMUX('B', 15, AF1)>;
			};

			/omit-if-no-ref/ tim16_ch1_pa6: tim16_ch1_pa6 {
				pinmux = <STM32_PINMUX('A', 6, AF1)>;
			};

			/omit-if-no-ref/ tim16_ch1_pa12: tim16_ch1_pa12 {
				pinmux = <STM32_PINMUX('A', 12, AF1)>;
			};

			/omit-if-no-ref/ tim16_ch1n_pa13: tim16_ch1n_pa13 {
				pinmux = <STM32_PINMUX('A', 13, AF1)>;
			};

			/omit-if-no-ref/ tim16_ch1_pb4: tim16_ch1_pb4 {
				pinmux = <STM32_PINMUX('B', 4, AF1)>;
			};

			/omit-if-no-ref/ tim16_ch1n_pb6: tim16_ch1n_pb6 {
				pinmux = <STM32_PINMUX('B', 6, AF1)>;
			};

			/omit-if-no-ref/ tim16_ch1_pb8: tim16_ch1_pb8 {
				pinmux = <STM32_PINMUX('B', 8, AF1)>;
			};

			/omit-if-no-ref/ tim17_ch1_pa7: tim17_ch1_pa7 {
				pinmux = <STM32_PINMUX('A', 7, AF1)>;
			};

			/omit-if-no-ref/ tim17_ch1_pb5: tim17_ch1_pb5 {
				pinmux = <STM32_PINMUX('B', 5, AF10)>;
			};

			/omit-if-no-ref/ tim17_ch1n_pb7: tim17_ch1n_pb7 {
				pinmux = <STM32_PINMUX('B', 7, AF1)>;
			};

			/omit-if-no-ref/ tim17_ch1_pb9: tim17_ch1_pb9 {
				pinmux = <STM32_PINMUX('B', 9, AF1)>;
			};

			/omit-if-no-ref/ tim8_ch1n_pa7: tim8_ch1n_pa7 {
				pinmux = <STM32_PINMUX('A', 7, AF4)>;
			};

			/omit-if-no-ref/ tim8_ch2_pa14: tim8_ch2_pa14 {
				pinmux = <STM32_PINMUX('A', 14, AF5)>;
			};

			/omit-if-no-ref/ tim8_ch1_pa15: tim8_ch1_pa15 {
				pinmux = <STM32_PINMUX('A', 15, AF2)>;
			};

			/omit-if-no-ref/ tim8_ch2n_pb0: tim8_ch2n_pb0 {
				pinmux = <STM32_PINMUX('B', 0, AF4)>;
			};

			/omit-if-no-ref/ tim8_ch3n_pb1: tim8_ch3n_pb1 {
				pinmux = <STM32_PINMUX('B', 1, AF4)>;
			};

			/omit-if-no-ref/ tim8_ch1n_pb3: tim8_ch1n_pb3 {
				pinmux = <STM32_PINMUX('B', 3, AF4)>;
			};

			/omit-if-no-ref/ tim8_ch2n_pb4: tim8_ch2n_pb4 {
				pinmux = <STM32_PINMUX('B', 4, AF4)>;
			};

			/omit-if-no-ref/ tim8_ch3n_pb5: tim8_ch3n_pb5 {
				pinmux = <STM32_PINMUX('B', 5, AF3)>;
			};

			/omit-if-no-ref/ tim8_ch1_pb6: tim8_ch1_pb6 {
				pinmux = <STM32_PINMUX('B', 6, AF5)>;
			};

			/omit-if-no-ref/ tim8_ch2_pb8: tim8_ch2_pb8 {
				pinmux = <STM32_PINMUX('B', 8, AF10)>;
			};

			/omit-if-no-ref/ tim8_ch3_pb9: tim8_ch3_pb9 {
				pinmux = <STM32_PINMUX('B', 9, AF10)>;
			};

			/omit-if-no-ref/ tim8_ch1_pc6: tim8_ch1_pc6 {
				pinmux = <STM32_PINMUX('C', 6, AF4)>;
			};

			/omit-if-no-ref/ tim8_ch2_pc7: tim8_ch2_pc7 {
				pinmux = <STM32_PINMUX('C', 7, AF4)>;
			};

			/omit-if-no-ref/ tim8_ch3_pc8: tim8_ch3_pc8 {
				pinmux = <STM32_PINMUX('C', 8, AF4)>;
			};

			/omit-if-no-ref/ tim8_ch4_pc9: tim8_ch4_pc9 {
				pinmux = <STM32_PINMUX('C', 9, AF4)>;
			};

			/omit-if-no-ref/ tim8_ch1n_pc10: tim8_ch1n_pc10 {
				pinmux = <STM32_PINMUX('C', 10, AF4)>;
			};

			/omit-if-no-ref/ tim8_ch2n_pc11: tim8_ch2n_pc11 {
				pinmux = <STM32_PINMUX('C', 11, AF4)>;
			};

			/omit-if-no-ref/ tim8_ch3n_pc12: tim8_ch3n_pc12 {
				pinmux = <STM32_PINMUX('C', 12, AF4)>;
			};

			/omit-if-no-ref/ tim8_ch4n_pc13: tim8_ch4n_pc13 {
				pinmux = <STM32_PINMUX('C', 13, AF6)>;
			};

			/omit-if-no-ref/ tim8_ch4n_pd0: tim8_ch4n_pd0 {
				pinmux = <STM32_PINMUX('D', 0, AF6)>;
			};

			/omit-if-no-ref/ tim8_ch4_pd1: tim8_ch4_pd1 {
				pinmux = <STM32_PINMUX('D', 1, AF4)>;
			};

			/* UART_CTS / USART_CTS / LPUART_CTS */

			/omit-if-no-ref/ lpuart1_cts_pa6: lpuart1_cts_pa6 {
				pinmux = <STM32_PINMUX('A', 6, AF12)>;
				bias-pull-up;
			};

			/omit-if-no-ref/ usart1_cts_pa11: usart1_cts_pa11 {
				pinmux = <STM32_PINMUX('A', 11, AF7)>;
				bias-pull-up;
			};

			/omit-if-no-ref/ lpuart1_cts_pb13: lpuart1_cts_pb13 {
				pinmux = <STM32_PINMUX('B', 13, AF8)>;
				bias-pull-up;
			};

			/omit-if-no-ref/ usart2_cts_pa0: usart2_cts_pa0 {
				pinmux = <STM32_PINMUX('A', 0, AF7)>;
				bias-pull-up;
			};

			/omit-if-no-ref/ uart4_cts_pb7: uart4_cts_pb7 {
				pinmux = <STM32_PINMUX('B', 7, AF14)>;
				bias-pull-up;
			};

			/* UART_DE / USART_DE / LPUART_DE */

			/omit-if-no-ref/ usart1_de_pa12: usart1_de_pa12 {
				pinmux = <STM32_PINMUX('A', 12, AF7)>;
				drive-push-pull;
			};

			/omit-if-no-ref/ lpuart1_de_pb1: lpuart1_de_pb1 {
				pinmux = <STM32_PINMUX('B', 1, AF12)>;
				drive-push-pull;
			};

			/omit-if-no-ref/ lpuart1_de_pb12: lpuart1_de_pb12 {
				pinmux = <STM32_PINMUX('B', 12, AF8)>;
				drive-push-pull;
			};

			/omit-if-no-ref/ usart2_de_pa1: usart2_de_pa1 {
				pinmux = <STM32_PINMUX('A', 1, AF7)>;
				drive-push-pull;
			};

			/omit-if-no-ref/ uart4_de_pa15: uart4_de_pa15 {
				pinmux = <STM32_PINMUX('A', 15, AF8)>;
				drive-push-pull;
			};

			/* UART_RTS / USART_RTS / LPUART_RTS */

			/omit-if-no-ref/ usart1_rts_pa12: usart1_rts_pa12 {
				pinmux = <STM32_PINMUX('A', 12, AF7)>;
				drive-push-pull;
			};

			/omit-if-no-ref/ lpuart1_rts_pb1: lpuart1_rts_pb1 {
				pinmux = <STM32_PINMUX('B', 1, AF12)>;
				drive-push-pull;
			};

			/omit-if-no-ref/ lpuart1_rts_pb12: lpuart1_rts_pb12 {
				pinmux = <STM32_PINMUX('B', 12, AF8)>;
				drive-push-pull;
			};

			/omit-if-no-ref/ usart2_rts_pa1: usart2_rts_pa1 {
				pinmux = <STM32_PINMUX('A', 1, AF7)>;
				drive-push-pull;
			};

			/omit-if-no-ref/ uart4_rts_pa15: uart4_rts_pa15 {
				pinmux = <STM32_PINMUX('A', 15, AF8)>;
				drive-push-pull;
			};

			/* UART_RX / USART_RX / LPUART_RX */

			/omit-if-no-ref/ lpuart1_rx_pa3: lpuart1_rx_pa3 {
				pinmux = <STM32_PINMUX('A', 3, AF12)>;
			};

			/omit-if-no-ref/ usart1_rx_pa10: usart1_rx_pa10 {
				pinmux = <STM32_PINMUX('A', 10, AF7)>;
			};

			/omit-if-no-ref/ usart1_rx_pb7: usart1_rx_pb7 {
				pinmux = <STM32_PINMUX('B', 7, AF7)>;
			};

			/omit-if-no-ref/ lpuart1_rx_pb10: lpuart1_rx_pb10 {
				pinmux = <STM32_PINMUX('B', 10, AF8)>;
			};

			/omit-if-no-ref/ lpuart1_rx_pc0: lpuart1_rx_pc0 {
				pinmux = <STM32_PINMUX('C', 0, AF8)>;
			};

			/omit-if-no-ref/ usart1_rx_pc5: usart1_rx_pc5 {
				pinmux = <STM32_PINMUX('C', 5, AF7)>;
			};

			/omit-if-no-ref/ usart2_rx_pa3: usart2_rx_pa3 {
				pinmux = <STM32_PINMUX('A', 3, AF7)>;
			};

			/omit-if-no-ref/ usart2_rx_pa15: usart2_rx_pa15 {
				pinmux = <STM32_PINMUX('A', 15, AF7)>;
			};

			/omit-if-no-ref/ usart2_rx_pb4: usart2_rx_pb4 {
				pinmux = <STM32_PINMUX('B', 4, AF7)>;
			};

			/omit-if-no-ref/ uart4_rx_pc11: uart4_rx_pc11 {
				pinmux = <STM32_PINMUX('C', 11, AF5)>;
			};

			/* UART_TX / USART_TX / LPUART_TX */

			/omit-if-no-ref/ lpuart1_tx_pa2: lpuart1_tx_pa2 {
				pinmux = <STM32_PINMUX('A', 2, AF12)>;
				bias-pull-up;
			};

			/omit-if-no-ref/ usart1_tx_pa9: usart1_tx_pa9 {
				pinmux = <STM32_PINMUX('A', 9, AF7)>;
				bias-pull-up;
			};

			/omit-if-no-ref/ usart1_tx_pb6: usart1_tx_pb6 {
				pinmux = <STM32_PINMUX('B', 6, AF7)>;
				bias-pull-up;
			};

			/omit-if-no-ref/ lpuart1_tx_pb11: lpuart1_tx_pb11 {
				pinmux = <STM32_PINMUX('B', 11, AF8)>;
				bias-pull-up;
			};

			/omit-if-no-ref/ lpuart1_tx_pc1: lpuart1_tx_pc1 {
				pinmux = <STM32_PINMUX('C', 1, AF8)>;
				bias-pull-up;
			};

			/omit-if-no-ref/ usart1_tx_pc4: usart1_tx_pc4 {
				pinmux = <STM32_PINMUX('C', 4, AF7)>;
				bias-pull-up;
			};

			/omit-if-no-ref/ usart2_tx_pa2: usart2_tx_pa2 {
				pinmux = <STM32_PINMUX('A', 2, AF7)>;
				bias-pull-up;
			};

			/omit-if-no-ref/ usart2_tx_pa14: usart2_tx_pa14 {
				pinmux = <STM32_PINMUX('A', 14, AF7)>;
				bias-pull-up;
			};

			/omit-if-no-ref/ usart2_tx_pb3: usart2_tx_pb3 {
				pinmux = <STM32_PINMUX('B', 3, AF7)>;
				bias-pull-up;
			};

			/omit-if-no-ref/ uart4_tx_pc10: uart4_tx_pc10 {
				pinmux = <STM32_PINMUX('C', 10, AF5)>;
				bias-pull-up;
			};

		};
	};
};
